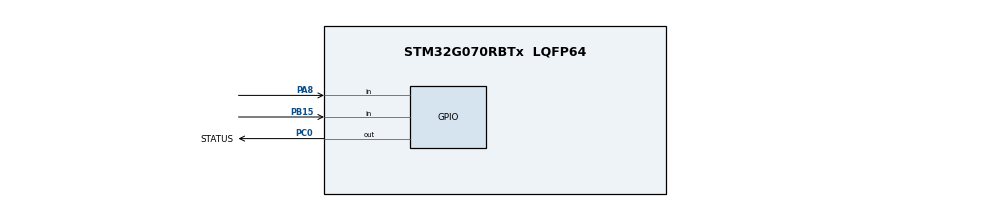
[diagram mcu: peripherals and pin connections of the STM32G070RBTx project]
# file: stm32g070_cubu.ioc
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Mcu.Family=STM32G0
Mcu.Name=STM32G070RBTx
Mcu.Package=LQFP64
PA13.Mode=Serial_Wire
PA13.Signal=SYS_SWDIO
PA14-BOOT0.Mode=Serial_Wire
PA14-BOOT0.Signal=SYS_SWCLK
PA8.Signal=GPIO_Input
PB15.Signal=GPIO_Input
PC0.GPIO_Label=STATUS
PC0.Signal=GPIO_Output
PF0-OSC_IN\ (PF0).Mode=HSE-External-Oscillator
PF0-OSC_IN\ (PF0).Signal=RCC_OSC_IN
PF1-OSC_OUT\ (PF1).Mode=HSE-External-Oscillator
PF1-OSC_OUT\ (PF1).Signal=RCC_OSC_OUT
ProjectManager.HeapSize=0x200
ProjectManager.StackSize=0x400
ProjectManager.TargetToolchain=STM32CubeIDE
RCC.ADCFreq_Value=64000000
RCC.AHBFreq_Value=64000000
RCC.CortexFreq_Value=64000000
RCC.EXTERNAL_CLOCK_VALUE=48000
RCC.HCLKFreq_Value=64000000
RCC.HSE_VALUE=8000000
RCC.HSI_VALUE=16000000
RCC.LSE_VALUE=32768
RCC.PLLN=16
RCC.PLLSourceVirtual=RCC_PLLSOURCE_HSE
RCC.SYSCLKFreq_VALUE=64000000
RCC.SYSCLKSource=RCC_SYSCLKSOURCE_PLLCLK
RCC.VCOOutputFreq_Value=128000000
board=custom

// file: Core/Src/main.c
/* USER CODE BEGIN Header */
/**
  ******************************************************************************
  * @file           : main.c
  * @brief          : Main program body
  ******************************************************************************
  * @attention
  *
  * Copyright (c) 2023 STMicroelectronics.
  * All rights reserved.
  *
  * This software is licensed under terms that can be found in the LICENSE file
  * in the root directory of this software component.
  * If no LICENSE file comes with this software, it is provided AS-IS.
  *
  ******************************************************************************
  */
/* USER CODE END Header */
#include "main.h"

void SystemClock_Config(void);
static void MX_GPIO_Init(void);

int main(void)
{

  /* MCU Configuration--------------------------------------------------------*/

  /* Reset of all peripherals, Initializes the Flash interface and the Systick. */
  HAL_Init();

  /* Configure the system clock */
  SystemClock_Config();

  /* Initialize all configured peripherals */
  MX_GPIO_Init();

  /* Infinite loop */
  /* USER CODE BEGIN WHILE */
  while (1)
  {
	  HAL_GPIO_TogglePin(STATUS_GPIO_Port, STATUS_Pin);
	  HAL_Delay(300);
	  /*for (volatile int i=0 ; i < 1000000 ; ++i)
	  {

	  }*/
    /* USER CODE END WHILE */

  }
}

void SystemClock_Config(void)
{
  LL_FLASH_SetLatency(LL_FLASH_LATENCY_2);
  while(LL_FLASH_GetLatency() != LL_FLASH_LATENCY_2)
  {
  }

  /* HSE configuration and activation */
  LL_RCC_HSE_Enable();
  while(LL_RCC_HSE_IsReady() != 1)
  {
  }

  /* Main PLL configuration and activation */
  LL_RCC_PLL_ConfigDomain_SYS(LL_RCC_PLLSOURCE_HSE, LL_RCC_PLLM_DIV_1, 16, LL_RCC_PLLR_DIV_2);
  LL_RCC_PLL_Enable();
  LL_RCC_PLL_EnableDomain_SYS();
  while(LL_RCC_PLL_IsReady() != 1)
  {
  }

  /* Set AHB prescaler*/
  LL_RCC_SetAHBPrescaler(LL_RCC_SYSCLK_DIV_1);

  /* Sysclk activation on the main PLL */
  LL_RCC_SetSysClkSource(LL_RCC_SYS_CLKSOURCE_PLL);
  while(LL_RCC_GetSysClkSource() != LL_RCC_SYS_CLKSOURCE_STATUS_PLL)
  {
  }

  /* Set APB1 prescaler*/
  LL_RCC_SetAPB1Prescaler(LL_RCC_APB1_DIV_1);
  /* Update CMSIS variable (which can be updated also through SystemCoreClockUpdate function) */
  LL_SetSystemCoreClock(64000000);

   /* Update the time base */
  if (HAL_InitTick (TICK_INT_PRIORITY) != HAL_OK)
  {
    Error_Handler();
  }
}

static void MX_GPIO_Init(void)
{
  GPIO_InitTypeDef GPIO_InitStruct = {0};

  /* GPIO Ports Clock Enable */
  __HAL_RCC_GPIOF_CLK_ENABLE();
  __HAL_RCC_GPIOC_CLK_ENABLE();
  __HAL_RCC_GPIOB_CLK_ENABLE();
  __HAL_RCC_GPIOA_CLK_ENABLE();

  /*Configure GPIO pin Output Level */
  HAL_GPIO_WritePin(STATUS_GPIO_Port, STATUS_Pin, GPIO_PIN_RESET);

  /*Configure GPIO pin : STATUS_Pin */
  GPIO_InitStruct.Pin = STATUS_Pin;
  GPIO_InitStruct.Mode = GPIO_MODE_OUTPUT_PP;
  GPIO_InitStruct.Pull = GPIO_NOPULL;
  GPIO_InitStruct.Speed = GPIO_SPEED_FREQ_LOW;
  HAL_GPIO_Init(STATUS_GPIO_Port, &GPIO_InitStruct);

  /*Configure GPIO pin : PB15 */
  GPIO_InitStruct.Pin = GPIO_PIN_15;
  GPIO_InitStruct.Mode = GPIO_MODE_INPUT;
  GPIO_InitStruct.Pull = GPIO_NOPULL;
  HAL_GPIO_Init(GPIOB, &GPIO_InitStruct);

  /*Configure GPIO pin : PA8 */
  GPIO_InitStruct.Pin = GPIO_PIN_8;
  GPIO_InitStruct.Mode = GPIO_MODE_INPUT;
  GPIO_InitStruct.Pull = GPIO_NOPULL;
  HAL_GPIO_Init(GPIOA, &GPIO_InitStruct);

}

void Error_Handler(void)
{
  __disable_irq();
  while (1)
  {
  }
}
